# ESP32-C5 register map
Vendor: ESPRESSIF SYSTEMS (SHANGHAI) CO., LTD.; Series: ESP32 C-Series; File version: 1
CPU: RV32IMAC r0p0, little endian, no MPU, no FPU, 0 interrupt priority bits
Address unit: 32 bits
Registers are 32-bit, read-write, reset 0x0 unless marked. A register's access mark holds for its fields unless they carry their own. Offsets are from the block's base; [hi:lo] are bit positions; {n}, {i} and the like mark numbered series.

## SHA — SHA (Secure Hash Algorithm) Accelerator
Base 0x60089000
0x00 MODE — Configures SHA algorithm
  [2:0] MODE — Configures the SHA algorithm. \\ 0: SHA-1\\ 1: SHA-224\\ 2: SHA-256\\
0x04 T_STRING — SHA 512/t configuration register 0.
  [31:0] T_STRING — Sha t_string (used if and only if mode == SHA_512/t).
0x08 T_LENGTH — SHA 512/t configuration register 1.
  [5:0] T_LENGTH — Sha t_length (used if and only if mode == SHA_512/t).
0x0C DMA_BLOCK_NUM — Block number register (only effective for DMA-SHA)
  [5:0] DMA_BLOCK_NUM — Configures the DMA-SHA block number.
0x10 START ro — Starts the SHA accelerator for Typical SHA operation
  [31:1] START — Write 1 to start Typical SHA calculation.
0x14 CONTINUE ro — Continues SHA operation (only effective in Typical SHA mode)
  [31:1] CONTINUE — Write 1 to continue Typical SHA calculation.
0x18 BUSY ro — Represents if SHA Accelerator is busy or not
  [0] STATE — Represents the states of SHA accelerator. \\ 0: idle\\ 1: busy\\
0x1C DMA_START wo — Starts the SHA accelerator for DMA-SHA operation
  [0] DMA_START — Write 1 to start DMA-SHA calculation.
0x20 DMA_CONTINUE wo — Continues SHA operation (only effective in DMA-SHA mode)
  [0] DMA_CONTINUE — Write 1 to continue DMA-SHA calculation.
0x24 CLEAR_IRQ wo — DMA-SHA interrupt clear register
  [0] CLEAR_INTERRUPT — Write 1 to clear DMA-SHA interrupt.
0x28 IRQ_ENA — DMA-SHA interrupt enable register
  [0] INTERRUPT_ENA — Write 1 to enable DMA-SHA interrupt.
0x2C DATE reset 0x20201229 — Version control register
  [29:0] DATE — Version control register.
{0x40+i} H_MEM[{i}] (i=0..63) 8-bit access not given — Sha H memory which contains intermediate hash or finial hash.
{0x80+i} M_MEM[{i}] (i=0..63) 8-bit access not given — Sha M memory which contains message.
0x800 _3_MODE — Initial configuration register 0.
  [2:0] _3_MODE — Sha3 mode
0x804 _3_CLEAN_M wo — Initial configuration register 1.
  [0] _3_CLEAN_M — Clean Message.
0x80C _3_DMA_BLOCK_NUM — DMA configuration register 0.
  [5:0] _3_DMA_BLOCK_NUM — DMA-SHA3 block number.
0x810 _3_START wo — Typical SHA3 configuration register 0.
  [0] _3_START — Start typical sha3.
0x814 _3_CONTINUE wo — Typical SHA3 configuration register 1.
  [0] _3_CONTINUE — Continue typical sha3.
0x818 _3_BUSY ro — Busy register.
  [0] _3_BUSY — Sha3 busy state. 1'b0: idle. 1'b1: busy.
0x81C _3_DMA_START wo — DMA configuration register 1.
  [0] _3_DMA_START — Start dma-sha3.
0x820 _3_DMA_CONTINUE wo — DMA configuration register 2.
  [0] _3_DMA_CONTINUE — Continue dma-sha3.
0x824 _3_CLEAR_INT wo — Interrupt clear register.
  [0] _3_CLEAR_INT — Clear sha3 interrupt.
0x828 _3_INT_ENA — Interrupt enable register.
  [0] _3_INT_ENA — Sha3 interrupt enable register. 1'b0: disable(default). 1'b1:enable
0x82C _3_SHAKE_LENGTH wo reset 0x32 — DMA configuration register 3.
  [10:0] _3_SHAKE_LENGTH — SHAKE output hash word length
{0x900+i} _3_M_OUT_MEM[{i}] (i=0..199) 8-bit access not given — Sha3 hash reg which contains intermediate hash or finial hash.
{0xA00+i} _3_M_MEM[{i}] (i=0..199) 8-bit access not given — Sha3 message reg which contains message.

## TEE — TEE Peripheral
Base 0x60098000
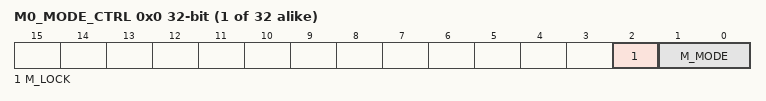
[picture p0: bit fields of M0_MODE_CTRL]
{0x0+4i} M{i}_MODE_CTRL (i=0..31) — TEE mode control register
  [2] M_LOCK — Set 1 to lock m0 tee configuration
  [1:0] M_MODE — Configures M%s security level mode.\\ 0: tee_mode \\ 1: ree_mode0 \\ 2: ree_mode1 \\ 3: ree_mode2 \\
0x80 CLOCK_GATE reset 0x1 — Clock gating register
  [0] CLK_EN — Configures whether to keep the clock always on.\\ 0: enable automatic clock gating \\ 1: keep the clock always on \\
0xFFC DATE reset 0x2212160 — Version control register
  [27:0] DATE
